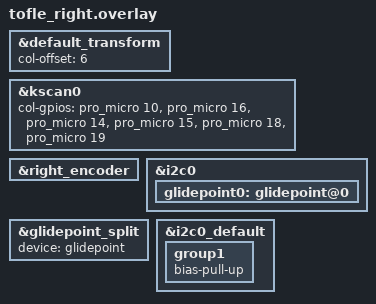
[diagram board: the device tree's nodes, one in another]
/*
 * Copyright (c) 2020 Ryan Cross
 *
 * SPDX-License-Identifier: MIT
 */

#include "tofle.dtsi"

&default_transform {
    col-offset = <6>;
};

&kscan0 {
    col-gpios
        = <&pro_micro 10 GPIO_ACTIVE_HIGH>
        , <&pro_micro 16 GPIO_ACTIVE_HIGH>
        , <&pro_micro 14 GPIO_ACTIVE_HIGH>
        , <&pro_micro 15 GPIO_ACTIVE_HIGH>
        , <&pro_micro 18 GPIO_ACTIVE_HIGH>
        , <&pro_micro 19 GPIO_ACTIVE_HIGH>
        ;
};

&right_encoder {
    status = "okay";
};

&i2c0 {
    status = "okay";
    glidepoint0: glidepoint@0 {
        status = "okay";
    };
};

&glidepoint_split {
    device = <&glidepoint>;
};

&i2c0_default {
    group1 {
      bias-pull-up;
    };
};

